# PIC32MZ1025DAA176 register map
Vendor: Microchip
Registers are 32-bit, read-write, reset 0x0 unless marked. A register's access mark holds for its fields unless they carry their own. Addresses are absolute, and some are shared; only a register's first bit layout is shown; [hi:lo] are bit positions; {n}, {i} and the like mark numbered series; 'fields as' and 'values as' point back to an identical list.

## lpwr_deep_sleep_ctrl
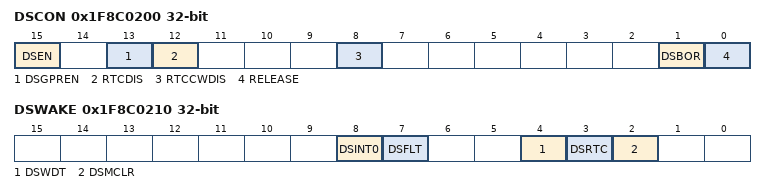
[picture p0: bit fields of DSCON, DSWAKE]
0x1F8C0200 DSCON
  [15] DSEN, [13] DSGPREN, [12] RTCDIS, [8] RTCCWDIS, [1] DSBOR, [0] RELEASE
0x1F8C0210 DSWAKE
  [8] DSINT0, [7] DSFLT, [4] DSWDT, [3] DSRTC, [2] DSMCLR
0x1F8C0220 DSGPR0
  [31:0] DSGPR
{0x1F8C023C+4i} DSGPR{i} (i=1..32)
  [31:0] DSGPR

## PCACHE
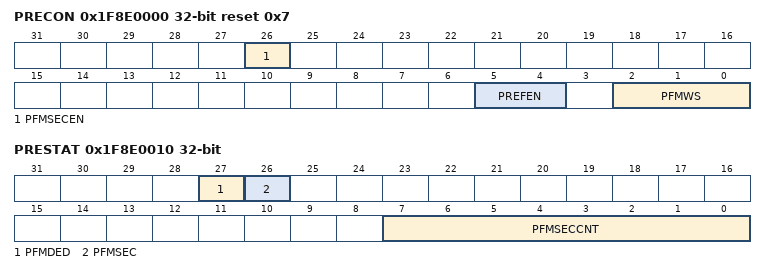
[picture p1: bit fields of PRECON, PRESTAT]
0x1F8E0000 PRECON reset 0x7
  [26] PFMSECEN, [5:4] PREFEN, [2:0] PFMWS
0x1F8E0010 PRESTAT
  [27] PFMDED, [26] PFMSEC, [7:0] PFMSECCNT

## EBI
{0x1F8E1014+4i} EBICS{i} (i=0..3)
  [31:16] CSADDR
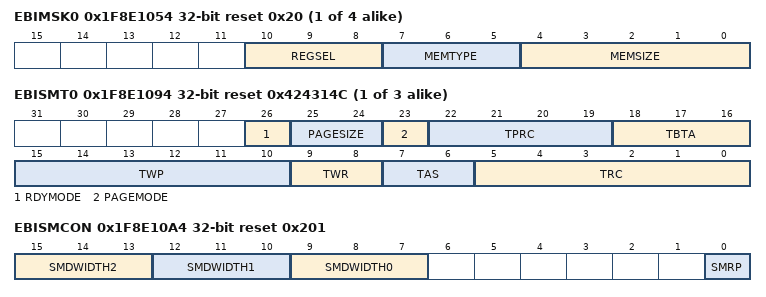
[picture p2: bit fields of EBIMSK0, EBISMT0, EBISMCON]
{0x1F8E1054+4i} EBIMSK{i} reset 0x20 (i=0..3)
  [10:8] REGSEL, [7:5] MEMTYPE, [4:0] MEMSIZE
{0x1F8E1094+4i} EBISMT{i} reset 0x424314C (i=0..2)
  [26] RDYMODE, [25:24] PAGESIZE, [23] PAGEMODE, [22:19] TPRC, [18:16] TBTA, [15:10] TWP, [9:8] TWR, [7:6] TAS, [5:0] TRC
0x1F8E10A0 EBIFTRPD reset 0x201
  [31:0] TRPD
0x1F8E10A4 EBISMCON reset 0x201
  [15:13] SMDWIDTH2, [12:10] SMDWIDTH1, [9:7] SMDWIDTH0, [0] SMRP

## DOS_EIP_00124_usb_hs_otgcore
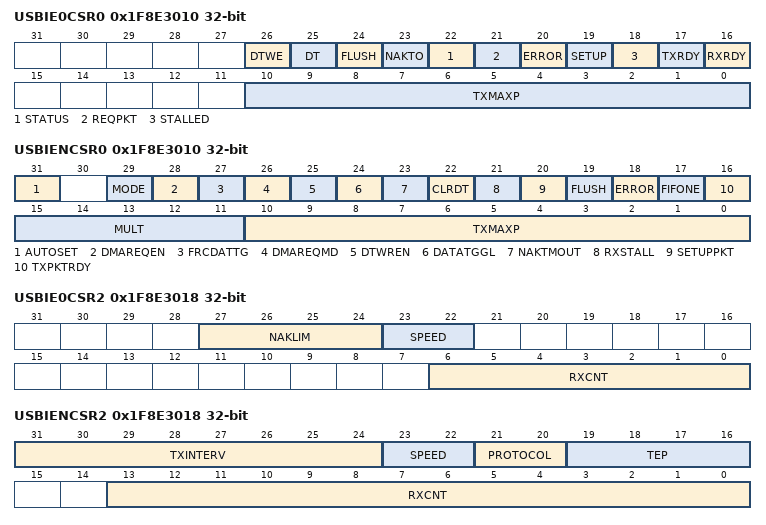
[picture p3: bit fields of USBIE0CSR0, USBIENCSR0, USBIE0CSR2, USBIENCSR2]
0x1F8E3010 USBIE0CSR0
  [26] DTWE, [25] DT, [24] FLUSH, [23] NAKTO, [22] STATUS, [21] REQPKT, [20] ERROR, [19] SETUP, [18] STALLED, [17] TXRDY, [16] RXRDY, [10:0] TXMAXP
0x1F8E3010 USBIENCSR0
  [31] AUTOSET, [29] MODE, [28] DMAREQEN, [27] FRCDATTG, [26] DMAREQMD, [25] DTWREN, [24] DATATGGL, [23] NAKTMOUT, [22] CLRDT, [21] RXSTALL, [20] SETUPPKT, [19] FLUSH, [18] ERROR, [17] FIFONE, [16] TXPKTRDY, [15:11] MULT, [10:0] TXMAXP
0x1F8E3018 USBIE0CSR2
  [27:24] NAKLIM, [23:22] SPEED, [6:0] RXCNT ro
0x1F8E3018 USBIENCSR2
  [31:24] TXINTERV, [23:22] SPEED, [21:20] PROTOCOL, [19:16] TEP, [13:0] RXCNT ro
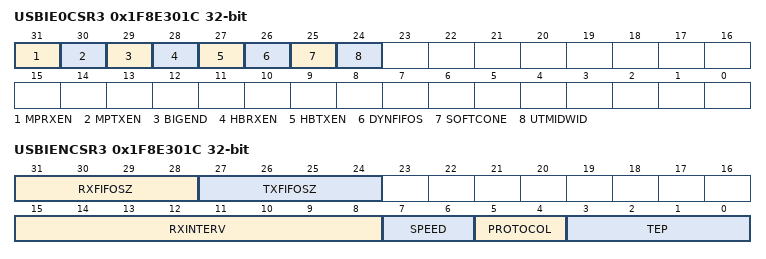
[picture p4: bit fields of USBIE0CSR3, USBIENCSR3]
0x1F8E301C USBIE0CSR3 ro reset not defined — (power-on value xx0xxx10------------------------)
  [31] MPRXEN, [30] MPTXEN, [29] BIGEND, [28] HBRXEN, [27] HBTXEN, [26] DYNFIFOS, [25] SOFTCONE, [24] UTMIDWID
0x1F8E301C USBIENCSR3 reset not defined — (power-on value xxxxxxxx--------0000000000000000)
  [31:28] RXFIFOSZ ro, [27:24] TXFIFOSZ ro, [15:8] RXINTERV, [7:6] SPEED, [5:4] PROTOCOL, [3:0] TEP

## RNG
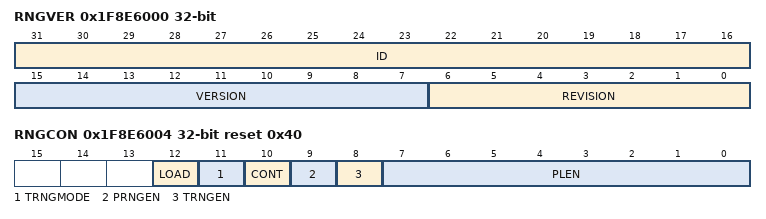
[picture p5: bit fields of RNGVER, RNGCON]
0x1F8E6000 RNGVER ro
  [31:16] ID, [15:7] VERSION, [6:0] REVISION
0x1F8E6004 RNGCON reset 0x40
  [12] LOAD, [11] TRNGMODE, [10] CONT, [9] PRNGEN, [8] TRNGEN, [7:0] PLEN
0x1F8E6008 RNGPOLY1 reset 0xFFFF0000
  [31:0] POLY
0x1F8E600C RNGPOLY2 reset 0xFFFF0000
  [31:0] POLY
0x1F8E6010 RNGNUMGEN1 reset 0xFFFFFFFF
  [31:0] RNG
0x1F8E6014 RNGNUMGEN2 reset 0xFFFFFFFF
  [31:0] RNG
0x1F8E6018 RNGSEED1 ro
  [31:0] SEED
0x1F8E601C RNGSEED2 ro
  [31:0] SEED
0x1F8E6020 RNGCNT
  [6:0] RCNT

## DOS_EIP_00160_gfx_gdc_ctlr
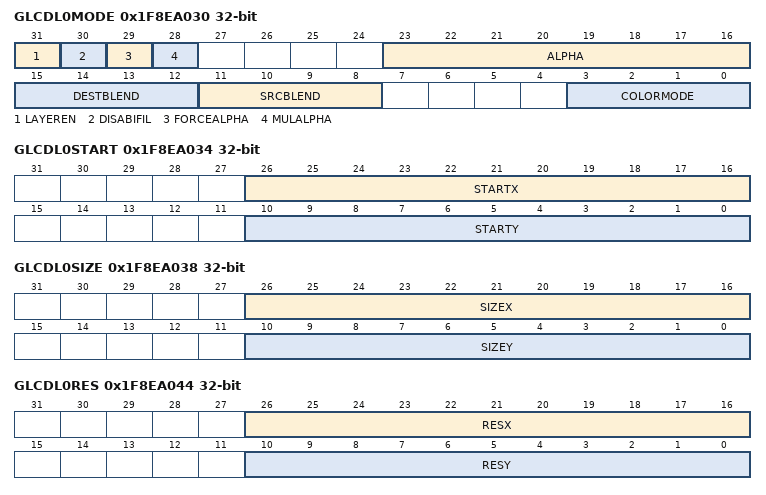
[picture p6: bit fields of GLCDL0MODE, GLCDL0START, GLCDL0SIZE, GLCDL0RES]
0x1F8EA030 GLCDL0MODE
  [31] LAYEREN, [30] DISABIFIL, [29] FORCEALPHA, [28] MULALPHA, [23:16] ALPHA, [15:12] DESTBLEND, [11:8] SRCBLEND, [3:0] COLORMODE
0x1F8EA034 GLCDL0START
  [26:16] STARTX, [10:0] STARTY
0x1F8EA038 GLCDL0SIZE
  [26:16] SIZEX, [10:0] SIZEY
0x1F8EA03C GLCDL0BADDR
  [31:0] BASEADDR
0x1F8EA040 GLCDL0STRIDE
  [15:0] STRIDE
0x1F8EA044 GLCDL0RES
  [26:16] RESX, [10:0] RESY
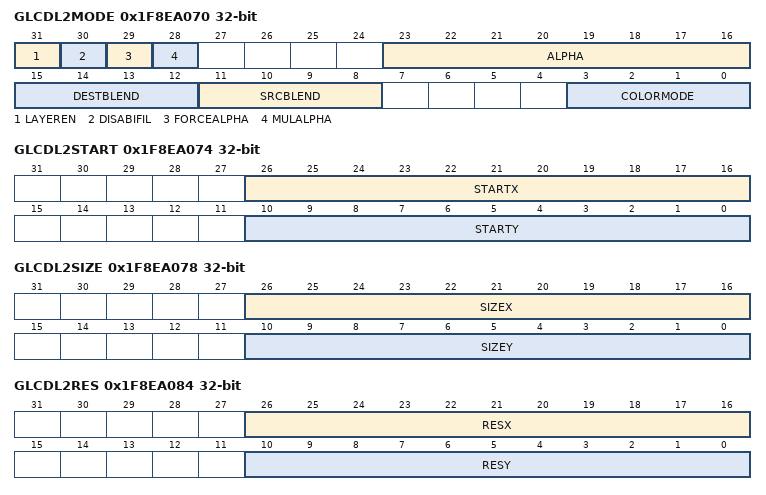
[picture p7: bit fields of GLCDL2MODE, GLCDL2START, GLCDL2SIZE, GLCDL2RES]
0x1F8EA070 GLCDL2MODE
  fields as GLCDL0MODE
0x1F8EA074 GLCDL2START
  [26:16] STARTX, [10:0] STARTY
0x1F8EA078 GLCDL2SIZE
  [26:16] SIZEX, [10:0] SIZEY
0x1F8EA07C GLCDL2BADDR
  [31:0] BASEADDR
0x1F8EA080 GLCDL2STRIDE
  [15:0] STRIDE
0x1F8EA084 GLCDL2RES
  [26:16] RESX, [10:0] RESY
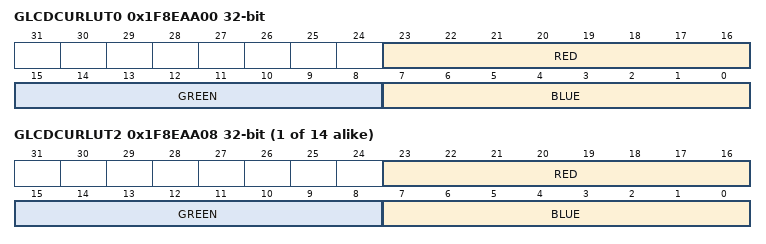
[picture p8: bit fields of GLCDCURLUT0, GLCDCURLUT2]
0x1F8EAA00 GLCDCURLUT0
  [23:16] RED, [15:8] GREEN, [7:0] BLUE
{0x1F8EAA00+4i} GLCDCURLUT{i} (i=2..15)
  [23:16] RED, [15:8] GREEN, [7:0] BLUE

## GPU
0x1F8EB000 GPUBASEADDR

## SDHC
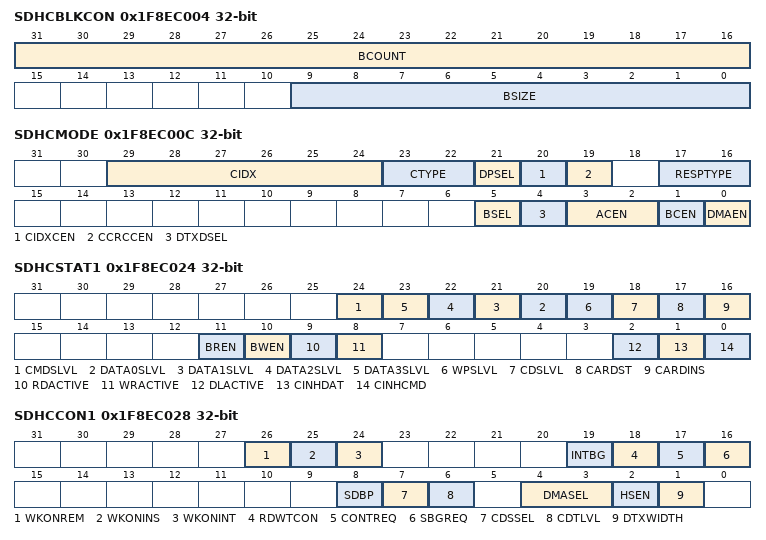
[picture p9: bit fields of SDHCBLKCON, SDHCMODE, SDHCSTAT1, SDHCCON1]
0x1F8EC004 SDHCBLKCON
  [31:16] BCOUNT, [9:0] BSIZE
0x1F8EC008 SDHCARG
  [31:0] ARG
0x1F8EC00C SDHCMODE
  [29:24] CIDX, [23:22] CTYPE, [21] DPSEL, [20] CIDXCEN, [19] CCRCCEN, [17:16] RESPTYPE, [5] BSEL, [4] DTXDSEL, [3:2] ACEN, [1] BCEN, [0] DMAEN
0x1F8EC014 SDHCRESP1 ro
  [31:0] RESP
0x1F8EC020 SDHCDATA
  [31:0] DATA
0x1F8EC024 SDHCSTAT1 ro reset not defined — (power-on value -------xxxxxxxxx----0000-----000)
  [24] CMDSLVL, [n+20] DATA{n}SLVL (n=0..3), [19] WPSLVL, [18] CDSLVL, [17] CARDST, [16] CARDINS, [11] BREN, [10] BWEN, [9] RDACTIVE, [8] WRACTIVE, [2] DLACTIVE, [1] CINHDAT, [0] CINHCMD
0x1F8EC028 SDHCCON1
  [26] WKONREM, [25] WKONINS, [24] WKONINT, [19] INTBG, [18] RDWTCON, [17] CONTREQ, [16] SBGREQ, [8] SDBP, [7] CDSSEL, [6] CDTLVL, [4:3] DMASEL, [2] HSEN, [1] DTXWIDTH
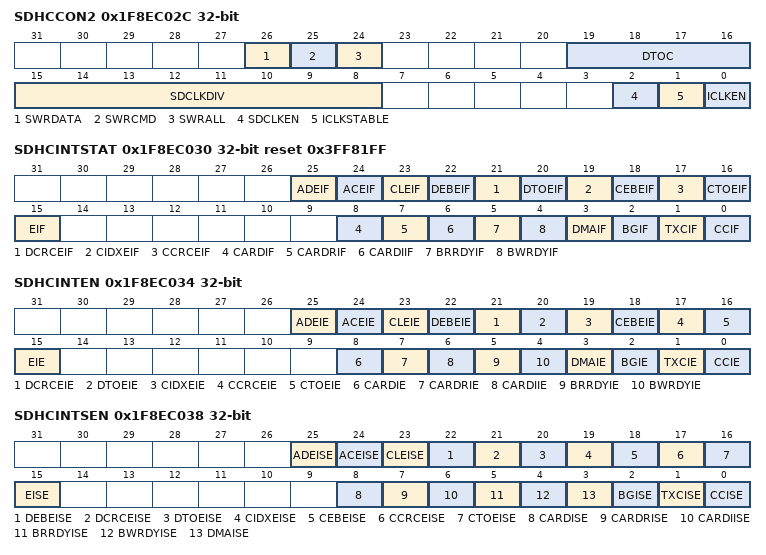
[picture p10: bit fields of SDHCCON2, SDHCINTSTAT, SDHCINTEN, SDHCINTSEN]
0x1F8EC02C SDHCCON2
  [26] SWRDATA, [25] SWRCMD, [24] SWRALL, [19:16] DTOC, [15:8] SDCLKDIV, [2] SDCLKEN, [1] ICLKSTABLE, [0] ICLKEN
0x1F8EC030 SDHCINTSTAT ro reset 0x3FF81FF
  [25] ADEIF, [24] ACEIF, [23] CLEIF, [22] DEBEIF, [21] DCRCEIF, [20] DTOEIF, [19] CIDXEIF, [18] CEBEIF, [17] CCRCEIF, [16] CTOEIF, [15] EIF, [8] CARDIF, [7] CARDRIF, [6] CARDIIF, [5] BRRDYIF, [4] BWRDYIF, [3] DMAIF, [2] BGIF, [1] TXCIF, [0] CCIF
0x1F8EC034 SDHCINTEN
  [25] ADEIE, [24] ACEIE, [23] CLEIE, [22] DEBEIE, [21] DCRCEIE, [20] DTOEIE, [19] CIDXEIE, [18] CEBEIE, [17] CCRCEIE, [16] CTOEIE, [15] EIE, [8] CARDIE, [7] CARDRIE, [6] CARDIIE, [5] BRRDYIE, [4] BWRDYIE, [3] DMAIE, [2] BGIE, [1] TXCIE, [0] CCIE
0x1F8EC038 SDHCINTSEN
  [25] ADEISE, [24] ACEISE, [23] CLEISE, [22] DEBEISE, [21] DCRCEISE, [20] DTOEISE, [19] CIDXEISE, [18] CEBEISE, [17] CCRCEISE, [16] CTOEISE, [15] EISE, [8] CARDISE, [7] CARDRISE, [6] CARDIISE, [5] BRRDYISE, [4] BWRDYISE, [3] DMAISE, [2] BGISE, [1] TXCISE, [0] CCISE
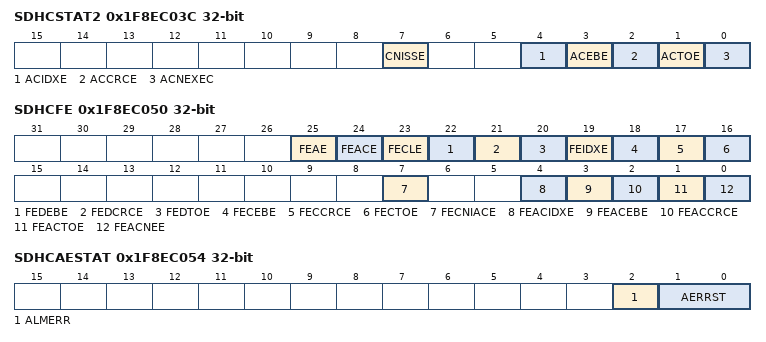
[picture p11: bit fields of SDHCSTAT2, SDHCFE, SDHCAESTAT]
0x1F8EC03C SDHCSTAT2 ro
  [7] CNISSE, [4] ACIDXE, [3] ACEBE, [2] ACCRCE, [1] ACTOE, [0] ACNEXEC
0x1F8EC040 SDHCCAP ro reset not defined — (power-on value -------1x-x-x-00--xxxxxx0-000000)
  [33:32] SLOTTYPE, [31] ASYNCINT, [26] VOLT3V3, [25] SRESUME, [23] HISPEED, [21] ADMA2, [20] BUS8BIT, [19:18] MBLEN, [15:8] BASECLK, [7] TOCLKU, [5:0] TOCLKFREQ
0x1F8EC048 SDHCMAXCAP ro reset not defined — (power-on value ------------------------xxxxxxxx)
  [7:0] MC3V3
0x1F8EC050 SDHCFE wo reset not defined — (power-on value ------xxxxxxxxxx--------x--xxxxx)
  [25] FEAE, [24] FEACE, [23] FECLE, [22] FEDEBE, [21] FEDCRCE, [20] FEDTOE, [19] FEIDXE, [18] FECEBE, [17] FECCRCE, [16] FECTOE, [7] FECNIACE, [4] FEACIDXE, [3] FEACEBE, [2] FEACCRCE, [1] FEACTOE, [0] FEACNEE
0x1F8EC054 SDHCAESTAT ro
  [2] ALMERR, [1:0] AERRST
0x1F8EC058 SDHCAADDR
  [31:0] ADDR

## DOS_EIP_00187_emb_sdio
0x1F8EC010 SDHCRESP0 ro
  [31:0] RESP
0x1F8EC018 SDHCRESP2 ro
  [31:0] RESP
0x1F8EC01C SDHCRESP3 ro
  [31:0] RESP

## SB
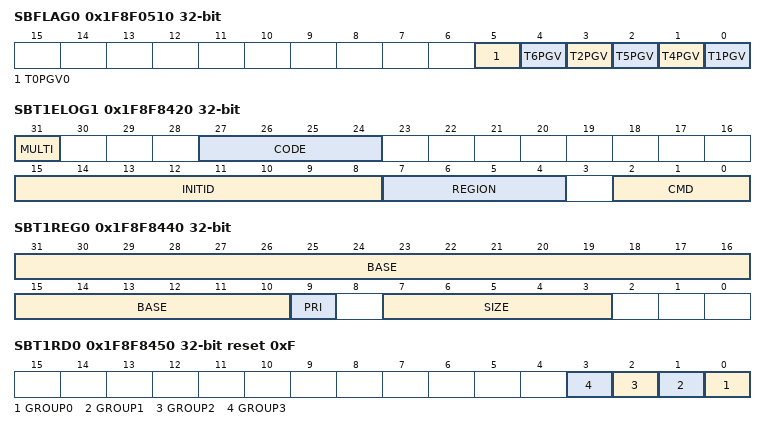
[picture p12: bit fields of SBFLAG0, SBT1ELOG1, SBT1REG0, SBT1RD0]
0x1F8F0510 SBFLAG0 ro
  [5] T0PGV0, [4] T6PGV, [3] T2PGV, [2] T5PGV, [1] T4PGV, [0] T1PGV
0x1F8F8420 SBT1ELOG1
  [31] MULTI, [27:24] CODE, [15:8] INITID ro, [7:4] REGION ro, [2:0] CMD ro
0x1F8F8424 SBT1ELOG2 ro
  [1:0] GROUP
0x1F8F8428 SBT1ECON
  [24] ERRP
0x1F8F8430 SBT1ECLRS ro
  [0] CLEAR
0x1F8F8438 SBT1ECLRM ro
  [0] CLEAR
0x1F8F8440 SBT1REG0 reset not defined — (power-on value 0000000000000000000000x-00000---)
  [31:10] BASE, [9] PRI ro, [7:3] SIZE
0x1F8F8450 SBT1RD0 reset 0xF
  [n] GROUP{n} (n=0..3)
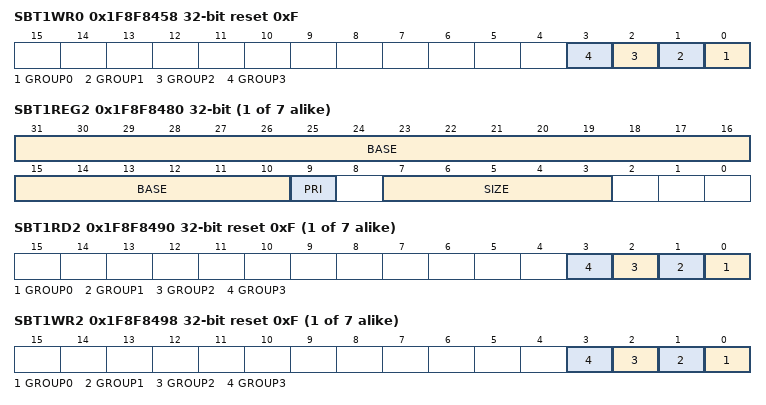
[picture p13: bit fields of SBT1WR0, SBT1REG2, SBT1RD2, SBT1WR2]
0x1F8F8458 SBT1WR0 reset 0xF
  [n] GROUP{n} (n=0..3)
{0x1F8F8440+0x20*i} SBT1REG{i} reset not defined (i=2..8) — (power-on value 0000000000000000000000x-00000---)
  [31:10] BASE, [9] PRI ro, [7:3] SIZE
{0x1F8F8450+0x20*i} SBT1RD{i} reset 0xF (i=2..8)
  [n] GROUP{n} (n=0..3)
{0x1F8F8458+0x20*i} SBT1WR{i} reset 0xF (i=2..8)
  [n] GROUP{n} (n=0..3)
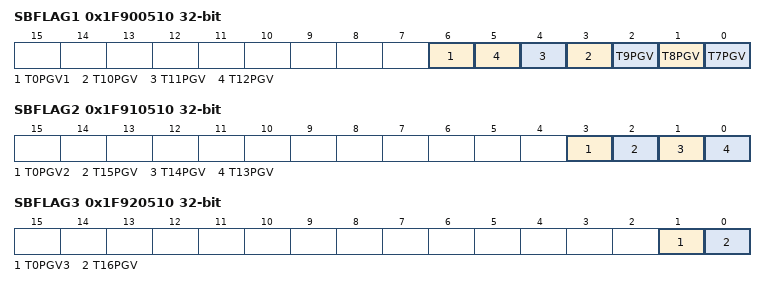
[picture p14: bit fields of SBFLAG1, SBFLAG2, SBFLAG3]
0x1F900510 SBFLAG1 ro
  [6] T0PGV1, [n-7] T{n}PGV (n=7..12)
0x1F910510 SBFLAG2 ro
  [3] T0PGV2, [2] T15PGV, [1] T14PGV, [0] T13PGV
0x1F920510 SBFLAG3 ro
  [1] T0PGV3, [0] T16PGV
